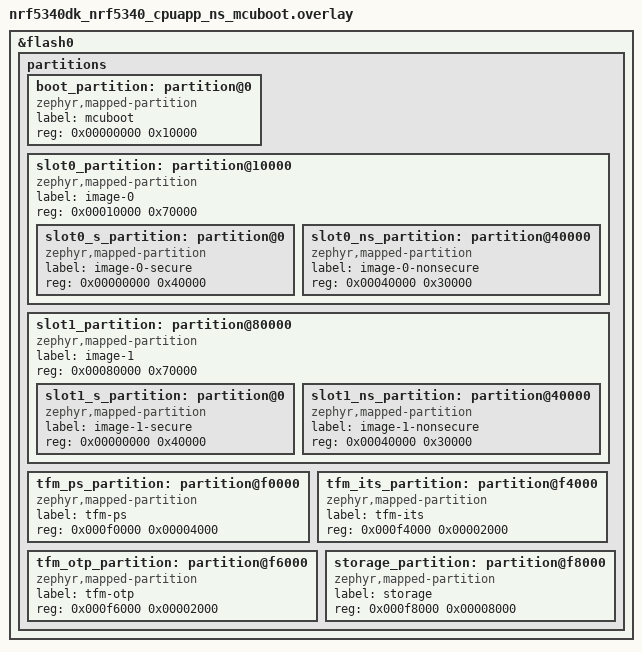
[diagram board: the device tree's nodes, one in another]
/delete-node/ &slot0_s_partition;
/delete-node/ &slot0_ns_partition;
/delete-node/ &tfm_its_partition;
/delete-node/ &tfm_otp_partition;
/delete-node/ &tfm_ps_partition;
/delete-node/ &tfm_storage_partition;

&flash0 {
	partitions {
		boot_partition: partition@0 {
			compatible = "zephyr,mapped-partition";
			label = "mcuboot";
			reg = <0x00000000 0x10000>;
		};

		slot0_partition: partition@10000 {
			compatible = "zephyr,mapped-partition";
			label = "image-0";
			reg = <0x00010000 0x70000>;
			ranges = <0x0 0x10000 0x70000>;
			#address-cells = <1>;
			#size-cells = <1>;

			slot0_s_partition: partition@0 {
				compatible = "zephyr,mapped-partition";
				label = "image-0-secure";
				reg = <0x00000000 0x40000>;
			};

			slot0_ns_partition: partition@40000 {
				compatible = "zephyr,mapped-partition";
				label = "image-0-nonsecure";
				reg = <0x00040000 0x30000>;
			};
		};

		slot1_partition: partition@80000 {
			compatible = "zephyr,mapped-partition";
			label = "image-1";
			reg = <0x00080000 0x70000>;
			ranges = <0x0 0x80000 0x70000>;
			#address-cells = <1>;
			#size-cells = <1>;

			slot1_s_partition: partition@0 {
				compatible = "zephyr,mapped-partition";
				label = "image-1-secure";
				reg = <0x00000000 0x40000>;
			};

			slot1_ns_partition: partition@40000 {
				compatible = "zephyr,mapped-partition";
				label = "image-1-nonsecure";
				reg = <0x00040000 0x30000>;
			};
		};

		tfm_ps_partition: partition@f0000 {
			compatible = "zephyr,mapped-partition";
			label = "tfm-ps";
			reg = <0x000f0000 0x00004000>;
		};

		tfm_its_partition: partition@f4000 {
			compatible = "zephyr,mapped-partition";
			label = "tfm-its";
			reg = <0x000f4000 0x00002000>;
		};

		tfm_otp_partition: partition@f6000 {
			compatible = "zephyr,mapped-partition";
			label = "tfm-otp";
			reg = <0x000f6000 0x00002000>;
		};

		storage_partition: partition@f8000 {
			compatible = "zephyr,mapped-partition";
			label = "storage";
			reg = <0x000f8000 0x00008000>;
		};
	};
};
